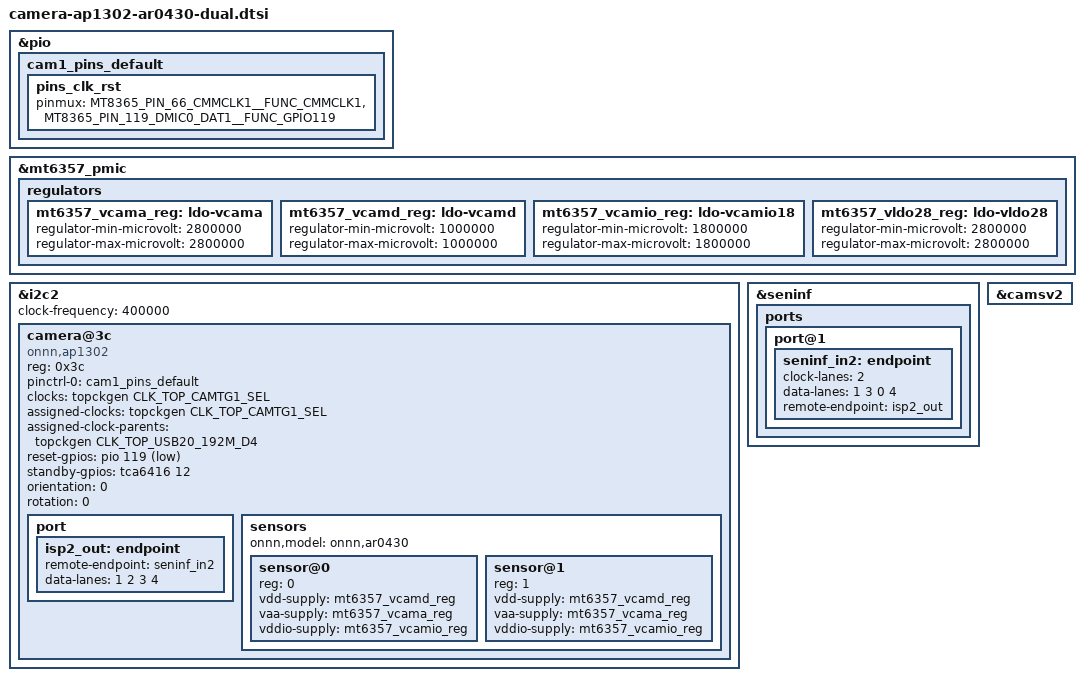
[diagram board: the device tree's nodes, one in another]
// SPDX-License-Identifier: GPL-2.0

#include <dt-bindings/clock/mt8365-clk.h>
#include <dt-bindings/gpio/gpio.h>
#include <dt-bindings/pinctrl/mt8365-pinfunc.h>

/dts-v1/;
/plugin/;

/ {
	fragment@0 {
		target = <&pio>;
		__overlay__ {
			cam1_pins_default: cam1_pins_default {
				pins_clk_rst {
					pinmux = <MT8365_PIN_66_CMMCLK1__FUNC_CMMCLK1>,
						 <MT8365_PIN_119_DMIC0_DAT1__FUNC_GPIO119>;
				};
			};
		};
	};

        fragment@1 {
                target = <&mt6357_pmic>;
                __overlay__ {
                        regulators {
                                mt6357_vcama_reg: ldo-vcama {
                                        regulator-min-microvolt = <2800000>;
                                        regulator-max-microvolt = <2800000>;
                                };

                                mt6357_vcamd_reg: ldo-vcamd {
                                        regulator-min-microvolt = <1000000>;
                                        regulator-max-microvolt = <1000000>;
                                };


                                mt6357_vcamio_reg: ldo-vcamio18 {
                                        regulator-min-microvolt = <1800000>;
                                        regulator-max-microvolt = <1800000>;
                                };


                                mt6357_vldo28_reg: ldo-vldo28 {
                                        regulator-min-microvolt = <2800000>;
                                        regulator-max-microvolt = <2800000>;
                                };
                        };
                };
        };


	fragment@2 {
		target = <&i2c2>;
		__overlay__ {
			clock-frequency = <400000>;

			camera@3c {  /* Main camera */
				compatible = "onnn,ap1302";
				reg = <0x3c>;

				pinctrl-names = "default";
				pinctrl-0 = <&cam1_pins_default>;

				clocks = <&topckgen CLK_TOP_CAMTG1_SEL>;
				assigned-clocks = <&topckgen CLK_TOP_CAMTG1_SEL>;
				assigned-clock-parents = <&topckgen CLK_TOP_USB20_192M_D4>;

				reset-gpios = <&pio 119 GPIO_ACTIVE_LOW>;
                                standby-gpios = <&tca6416 12 GPIO_ACTIVE_HIGH>;

				orientation = <0>;
				rotation = <0>;

				port {
					isp2_out: endpoint {
						remote-endpoint = <&seninf_in2>;
						data-lanes = <1 2 3 4>;
					};
				};

				sensors {
					#address-cells = <1>;
					#size-cells = <0>;

					onnn,model = "onnn,ar0430";

					sensor@0 {
						reg = <0>;

                                                vdd-supply = <&mt6357_vcamd_reg>;
                                                vaa-supply = <&mt6357_vcama_reg>;
                                                vddio-supply = <&mt6357_vcamio_reg>;
					};

                                        sensor@1 {
                                                reg = <1>;

                                                vdd-supply = <&mt6357_vcamd_reg>;
                                                vaa-supply = <&mt6357_vcama_reg>;
                                                vddio-supply = <&mt6357_vcamio_reg>;
                                        };
				};
			};
		};
	};

	fragment@3 {
		target = <&seninf>;
		__overlay__ {
			status = "okay";

			ports {
				port@1 {
					seninf_in2: endpoint {
						clock-lanes = <2>;
						data-lanes = <1 3 0 4>;
						remote-endpoint = <&isp2_out>;
					};
				};
			};
		};
	};

	fragment@4 {
		target = <&camsv2>;
		__overlay__ {
			status = "okay";
		};
	};
};
